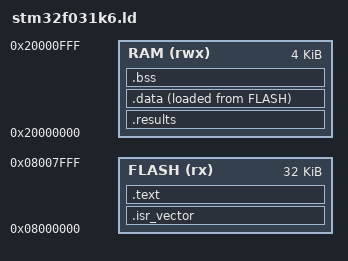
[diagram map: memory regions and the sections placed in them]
MEMORY
{
  FLASH (rx) : ORIGIN = 0x08000000, LENGTH = 32K
  RAM  (rwx) : ORIGIN = 0x20000000, LENGTH = 4K
}

_estack = ORIGIN(RAM) + LENGTH(RAM);

SECTIONS
{
  .isr_vector : { KEEP(*(.isr_vector)) } > FLASH
  .text   : { *(.text*) *(.rodata*) . = ALIGN(4); } > FLASH
  _sidata = LOADADDR(.data);

  /* fixed address so the host can read results without a symbol table */
  .results (NOLOAD) : { . = ALIGN(4); *(.results) . = ALIGN(4); } > RAM

  .data : { _sdata = .; *(.data*) . = ALIGN(4); _edata = .; } > RAM AT > FLASH
  .bss  : { _sbss = .; *(.bss*) *(COMMON) . = ALIGN(4); _ebss = .; } > RAM
}
